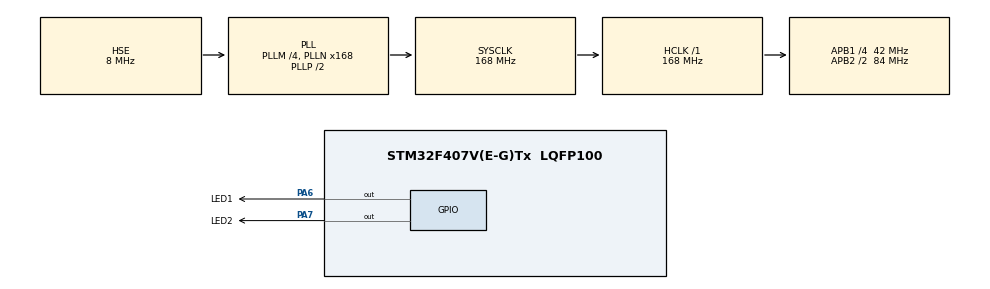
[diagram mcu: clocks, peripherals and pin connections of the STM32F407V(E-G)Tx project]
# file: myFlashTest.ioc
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Mcu.Family=STM32F4
RCC.PLLSourceVirtual=RCC_PLLSOURCE_HSE
PC15-OSC32_OUT.Mode=LSE-External-Oscillator
PH0-OSC_IN.Signal=RCC_OSC_IN
RCC.CortexFreq_Value=168000000
PA7.GPIO_ModeDefaultOutputPP=GPIO_MODE_OUTPUT_PP
PA6.PinState=GPIO_PIN_SET
PA6.GPIO_Label=LED1
RCC.APB1CLKDivider=RCC_HCLK_DIV4
PC14-OSC32_IN.Signal=RCC_OSC32_IN
RCC.SYSCLKSource=RCC_SYSCLKSOURCE_PLLCLK
ProjectManager.StackSize=0x400
PA13.Signal=SYS_JTMS-SWDIO
PA7.PinState=GPIO_PIN_SET
ProjectManager.TargetToolchain=STM32CubeIDE
RCC.HCLKFreq_Value=168000000
RCC.APB2TimFreq_Value=168000000
PC15-OSC32_OUT.Signal=RCC_OSC32_OUT
PA7.GPIO_PuPd=GPIO_PULLUP
RCC.AHBFreq_Value=168000000
PH0-OSC_IN.Mode=HSE-External-Oscillator
RCC.HSE_VALUE=8000000
board=custom
RCC.VCOOutputFreq_Value=336000000
PA7.GPIO_Speed=GPIO_SPEED_FREQ_HIGH
RCC.APB2Freq_Value=84000000
PA6.GPIO_PuPd=GPIO_PULLUP
PC14-OSC32_IN.Mode=LSE-External-Oscillator
PA14.Mode=Serial_Wire
PH1-OSC_OUT.Signal=RCC_OSC_OUT
PA13.Mode=Serial_Wire
Mcu.Name=STM32F407V(E-G)Tx
PH1-OSC_OUT.Mode=HSE-External-Oscillator
RCC.48MHZClocksFreq_Value=84000000
RCC.SYSCLKFreq_VALUE=168000000
Mcu.Package=LQFP100
PA6.Signal=GPIO_Output
PA7.GPIO_Label=LED2
PA14.Signal=SYS_JTCK-SWCLK
ProjectManager.HeapSize=0x200
RCC.HSI_VALUE=16000000
PA6.GPIO_ModeDefaultOutputPP=GPIO_MODE_OUTPUT_PP
NVIC.PriorityGroup=NVIC_PRIORITYGROUP_4
RCC.APB2CLKDivider=RCC_HCLK_DIV2
RCC.PLLM=4
RCC.PLLN=168
RCC.APB1TimFreq_Value=84000000
PA6.GPIO_Speed=GPIO_SPEED_FREQ_HIGH
RCC.APB1Freq_Value=42000000
PA7.Signal=GPIO_Output

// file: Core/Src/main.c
/* USER CODE BEGIN Header */
/**
  ******************************************************************************
  * @file           : main.c
  * @brief          : Main program body
  ******************************************************************************
  * @attention
  *
  * <h2><center>&copy; Copyright (c) 2021 STMicroelectronics.
  * All rights reserved.</center></h2>
  *
  * This software component is licensed by ST under BSD 3-Clause license,
  * the "License"; You may not use this file except in compliance with the
  * License. You may obtain a copy of the License at:
  *                        opensource.org/licenses/BSD-3-Clause
  *
  ******************************************************************************
  */
/* USER CODE END Header */
#include "main.h"

/* USER CODE BEGIN Includes */
#include <string.h>
/* USER CODE END Includes */

/* USER CODE BEGIN PD */
#define FLASH_STORAGE 0x08070000
#define page_size 0x800
/* USER CODE END PD */

/* USER CODE BEGIN PV */
uint8_t u8DataRead[4];
/* USER CODE END PV */

void SystemClock_Config(void);
static void MX_GPIO_Init(void);
/* USER CODE BEGIN PFP */
void vTestSaveToFlash();
void vTestReadToFlash();
/* USER CODE END PFP */

int main(void)
{

  /* MCU Configuration--------------------------------------------------------*/

  /* Reset of all peripherals, Initializes the Flash interface and the Systick. */
  HAL_Init();

  /* Configure the system clock */
  SystemClock_Config();

  /* Initialize all configured peripherals */
  MX_GPIO_Init();
  /* USER CODE BEGIN 2 */
  vTestSaveToFlash();
  HAL_Delay(100);
  vTestReadToFlash();
  /* USER CODE END 2 */

  /* Infinite loop */
  while (1)
  {

    /* USER CODE BEGIN 3 */
//	  HAL_GPIO_TogglePin(LED1_GPIO_Port, LED1_Pin);
//	  HAL_Delay(500);
  }
  /* USER CODE END 3 */
}

void SystemClock_Config(void)
{
  RCC_OscInitTypeDef RCC_OscInitStruct = {0};
  RCC_ClkInitTypeDef RCC_ClkInitStruct = {0};

  /** Configure the main internal regulator output voltage
  */
  __HAL_RCC_PWR_CLK_ENABLE();
  __HAL_PWR_VOLTAGESCALING_CONFIG(PWR_REGULATOR_VOLTAGE_SCALE1);
  /** Initializes the RCC Oscillators according to the specified parameters
  * in the RCC_OscInitTypeDef structure.
  */
  RCC_OscInitStruct.OscillatorType = RCC_OSCILLATORTYPE_HSE;
  RCC_OscInitStruct.HSEState = RCC_HSE_ON;
  RCC_OscInitStruct.PLL.PLLState = RCC_PLL_ON;
  RCC_OscInitStruct.PLL.PLLSource = RCC_PLLSOURCE_HSE;
  RCC_OscInitStruct.PLL.PLLM = 4;
  RCC_OscInitStruct.PLL.PLLN = 168;
  RCC_OscInitStruct.PLL.PLLP = RCC_PLLP_DIV2;
  RCC_OscInitStruct.PLL.PLLQ = 4;
  if (HAL_RCC_OscConfig(&RCC_OscInitStruct) != HAL_OK)
  {
    Error_Handler();
  }
  /** Initializes the CPU, AHB and APB buses clocks
  */
  RCC_ClkInitStruct.ClockType = RCC_CLOCKTYPE_HCLK|RCC_CLOCKTYPE_SYSCLK
                              |RCC_CLOCKTYPE_PCLK1|RCC_CLOCKTYPE_PCLK2;
  RCC_ClkInitStruct.SYSCLKSource = RCC_SYSCLKSOURCE_PLLCLK;
  RCC_ClkInitStruct.AHBCLKDivider = RCC_SYSCLK_DIV1;
  RCC_ClkInitStruct.APB1CLKDivider = RCC_HCLK_DIV4;
  RCC_ClkInitStruct.APB2CLKDivider = RCC_HCLK_DIV2;

  if (HAL_RCC_ClockConfig(&RCC_ClkInitStruct, FLASH_LATENCY_5) != HAL_OK)
  {
    Error_Handler();
  }
}

static void MX_GPIO_Init(void)
{
  GPIO_InitTypeDef GPIO_InitStruct = {0};

  /* GPIO Ports Clock Enable */
  __HAL_RCC_GPIOC_CLK_ENABLE();
  __HAL_RCC_GPIOH_CLK_ENABLE();
  __HAL_RCC_GPIOA_CLK_ENABLE();

  /*Configure GPIO pin Output Level */
  HAL_GPIO_WritePin(GPIOA, LED1_Pin|LED2_Pin, GPIO_PIN_SET);

  /*Configure GPIO pins : LED1_Pin LED2_Pin */
  GPIO_InitStruct.Pin = LED1_Pin|LED2_Pin;
  GPIO_InitStruct.Mode = GPIO_MODE_OUTPUT_PP;
  GPIO_InitStruct.Pull = GPIO_PULLUP;
  GPIO_InitStruct.Speed = GPIO_SPEED_FREQ_HIGH;
  HAL_GPIO_Init(GPIOA, &GPIO_InitStruct);

}

/* USER CODE BEGIN 4 */
void vTestSaveToFlash()
{
	volatile HAL_StatusTypeDef status;
	volatile uint32_t u32Temp = 0x0000fffa;
	HAL_FLASH_Unlock();
	HAL_FLASH_OB_Unlock();
	HAL_GPIO_WritePin(LED1_GPIO_Port, LED1_Pin, GPIO_PIN_SET);
	status = HAL_FLASH_Program(FLASH_TYPEPROGRAM_WORD, FLASH_STORAGE, u32Temp);
	if(status == HAL_OK)
		HAL_GPIO_WritePin(LED1_GPIO_Port, LED1_Pin, GPIO_PIN_RESET);
	HAL_FLASH_OB_Lock();
	HAL_FLASH_Lock();
}

void vTestReadToFlash()
{
	volatile uint32_t read_data;
	HAL_GPIO_WritePin(LED2_GPIO_Port, LED2_Pin, GPIO_PIN_SET);
	read_data = *(uint32_t*)(FLASH_STORAGE);
	if(read_data == 0x0000fffa)
		HAL_GPIO_WritePin(LED2_GPIO_Port, LED2_Pin, GPIO_PIN_RESET);
	u8DataRead[0] = (uint8_t)read_data;
	u8DataRead[1] = (uint8_t)(read_data >> 8);
	u8DataRead[2] = (uint8_t)(read_data >> 16);
	u8DataRead[3] = (uint8_t)(read_data >> 24);
}
/* USER CODE END 4 */

void Error_Handler(void)
{
  __disable_irq();
  while (1)
  {
  }
}

/************************ (C) COPYRIGHT STMicroelectronics *****END OF FILE****/
